# GD32F20x_CL register map
File version: 1.0
CPU: CM3 r2p1, little endian, no MPU, no FPU, 4 interrupt priority bits
Registers are 32-bit, read-write, reset 0x0 unless marked. A register's access mark holds for its fields unless they carry their own. Offsets are from the block's base; [hi:lo] are bit positions; {n}, {i} and the like mark numbered series; 'fields as' and 'values as' point back to an identical list.

## ENET_MSC — Ethernet: MAC statistics counters
Base 0x40028100
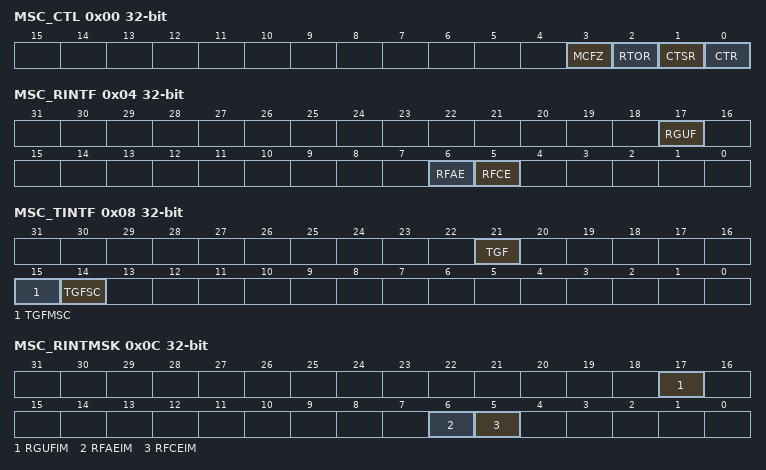
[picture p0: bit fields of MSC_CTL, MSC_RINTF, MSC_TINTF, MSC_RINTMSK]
0x00 MSC_CTL — Ethernet MSC control register (MSC_CTL)
  [3] MCFZ — MSC counter freeze
  [2] RTOR — Reset on read
  [1] CTSR — Counter stop rollover
  [0] CTR — Counter reset
0x04 MSC_RINTF ro — Ethernet MSC receive interrupt flag register (MSC_RINTF)
  [17] RGUF — Received Good Unicast Frames
  [6] RFAE — Received frames alignment error
  [5] RFCE — Received frames CRC error
0x08 MSC_TINTF ro — Ethernet MSC transmit interrupt flag register (MSC_TINTF)
  [21] TGF — Transmitted good frames
  [15] TGFMSC — Transmitted good frames more single collision
  [14] TGFSC — Transmitted good frames single collision
0x0C MSC_RINTMSK — Ethernet MSC receive interrupt mask register (MSC_RINTMSK)
  [17] RGUFIM — Received good unicast frames interrupt mask
  [6] RFAEIM — Received frames alignment error interrupt mask
  [5] RFCEIM — Received frame CRC error interrupt mask
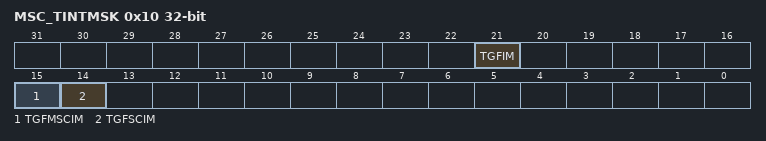
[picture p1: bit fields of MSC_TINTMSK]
0x10 MSC_TINTMSK — Ethernet MSC transmit interrupt mask register (MSC_TINTMSK)
  [21] TGFIM — Transmitted good frames interrupt mask
  [15] TGFMSCIM — Transmitted good frames more single interrupt collision mask
  [14] TGFSCIM — Transmitted good frames single collision interrupt mask
0x4C MSC_SCCNT ro — Ethernet MSC transmitted good frames after a single collision counter
  [31:0] SCC — Transmitted good frames after a single collision counter
0x50 MSC_MSCCNT ro — Ethernet MSC transmitted good frames after more than a single collision
  [31:0] MSCC — Transmitted good frames after more than a single collision counter
0x68 MSC_TGFCNT ro — Ethernet MSC transmitted good frames counter register
  [31:0] TGF — Transmitted good frames counter
0x94 MSC_RFCECNT ro — Ethernet MSC received frames with CRC error counter register
  [31:0] RFCER — Received frames with CRC error counter
0x98 MSC_RFAECNT ro — Ethernet MSC received frames with alignment error counter register
  [31:0] RFAER — Received frames with alignment error counter
0xC4 MSC_RGUFCNT ro — MSC received good unicast frames counter register
  [31:0] RGUF — Received good unicast frames counter

## ENET_PTP — Ethernet: Precision time protocol
Base 0x40028700
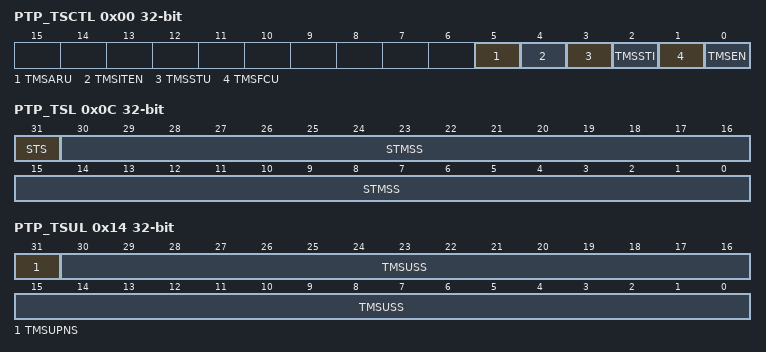
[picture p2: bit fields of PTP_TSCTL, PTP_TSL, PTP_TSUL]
0x00 PTP_TSCTL — Ethernet PTP time stamp control register (PTP_TSCTL)
  [5] TMSARU — Time stamp addend register update
  [4] TMSITEN — Time stamp interrupt trigger enable
  [3] TMSSTU — Time stamp system time update
  [2] TMSSTI — Time stamp system time initialize
  [1] TMSFCU — Time stamp fine or coarse update
  [0] TMSEN — Time stamp enable
0x04 PTP_SSINC — Ethernet PTP subsecond increment register
  [7:0] STMSSI — System time subsecond increment
0x08 PTP_TSH ro — Ethernet PTP time stamp high register
  [31:0] STMS — System time second
0x0C PTP_TSL ro — Ethernet PTP time stamp low register (PTP_TSL)
  [31] STS — System time sign
  [30:0] STMSS — System time subseconds
0x10 PTP_TSUH — Ethernet PTP time stamp high update register
  [31:0] TMSUS — Time stamp update second
0x14 PTP_TSUL — Ethernet PTP time stamp low update register (PTP_TSUL)
  [31] TMSUPNS — Time stamp update positive or negative sign
  [30:0] TMSUSS — Time stamp update subseconds
0x18 PTP_TSADDEND — Ethernet PTP time stamp addend register
  [31:0] TMSA — Time stamp addend
0x1C PTP_ETH — Ethernet PTP expected time high register
  [31:0] ETSH — Expected time stamp high
0x20 PTP_ETL — Ethernet PTP expected time low register
  [31:0] ETSL — Expected time stamp low

## EXMC — External memory controller
Base 0xA0000000
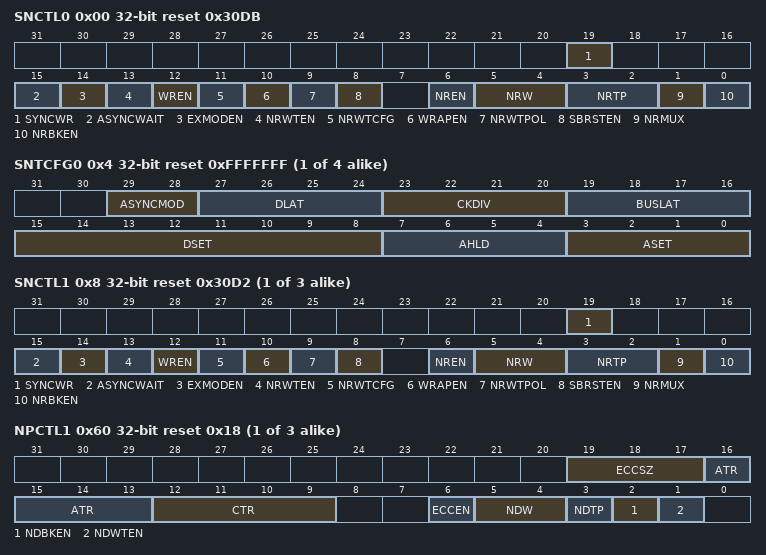
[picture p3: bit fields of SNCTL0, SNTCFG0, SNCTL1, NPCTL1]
0x00 SNCTL0 reset 0x30DB — SRAM/NOR flash control register 0
  [19] SYNCWR — Synchronous write
  [15] ASYNCWAIT — Asynchronous wait
  [14] EXMODEN — Extended mode enable
  [13] NRWTEN — NWAIT signal enable
  [12] WREN — Write enable
  [11] NRWTCFG — NWAIT signal configuration, only work in synchronous mode
  [10] WRAPEN — Wrapped burst mode enable
  [9] NRWTPOL — NWAIT signal polarity
  [8] SBRSTEN — Synchronous burst enable
  [6] NREN — NOR Flash access enable
  [5:4] NRW — NOR bank memory data bus width
  [3:2] NRTP — NOR bank memory type
  [1] NRMUX — NOR bank memory address/data multiplexing
  [0] NRBKEN — NOR bank enable
{0x4+8i} SNTCFG{i} reset 0xFFFFFFF (i=0..3) — SRAM/NOR flash timing configuration register {i}
  [29:28] ASYNCMOD — Asynchronous access mode
  [27:24] DLAT — Data latency for NOR Flash
  [23:20] CKDIV — Synchronous clock divide ratio
  [19:16] BUSLAT — Bus latency
  [15:8] DSET — Data setup time
  [7:4] AHLD — Address hold time
  [3:0] ASET — Address setup time
{0x0+8i} SNCTL{i} reset 0x30D2 (i=1..3) — SRAM/NOR flash control register {i}
  fields as SNCTL0
{0x40+0x20*i} NPCTL{i} reset 0x18 (i=1..3) — NAND flash/PC card control register {i}
  [19:17] ECCSZ — ECC size
  [16:13] ATR — ALE to RE delay
  [12:9] CTR — CLE to RE delay
  [6] ECCEN — ECC enable
  [5:4] NDW — NAND bank memory data bus width
  [3] NDTP — NAND bank memory type
  [2] NDBKEN — NAND bank enable
  [1] NDWTEN — Wait feature enable
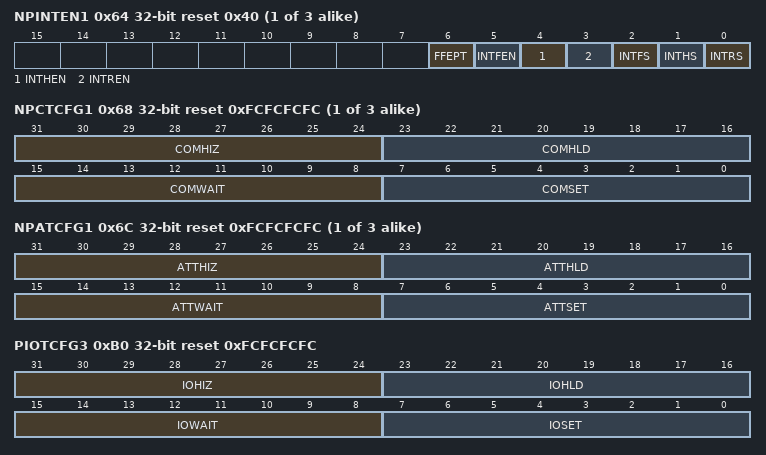
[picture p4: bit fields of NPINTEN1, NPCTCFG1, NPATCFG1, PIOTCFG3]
{0x44+0x20*i} NPINTEN{i} access per field reset 0x40 (i=1..3) — NAND flash/PC card interrupt enable register {i}
  [6] FFEPT ro — FIFO empty flag
  [5] INTFEN rw — Interrupt falling edge detection enable
  [4] INTHEN rw — Interrupt high-level detection enable
  [3] INTREN rw — Interrupt rising edge detection enable bit
  [2] INTFS rw — Interrupt falling edge status
  [1] INTHS rw — Interrupt high-level status
  [0] INTRS rw — Interrupt rising edge status
{0x48+0x20*i} NPCTCFG{i} reset 0xFCFCFCFC (i=1..3) — NAND flash/PC card common space timing configuration register {i}
  [31:24] COMHIZ — Common memory data bus HiZ time
  [23:16] COMHLD — Common memory hold time
  [15:8] COMWAIT — Common memory wait time
  [7:0] COMSET — Common memory setup time
{0x4C+0x20*i} NPATCFG{i} reset 0xFCFCFCFC (i=1..3) — NAND flash/PC card attribute space timing configuration register {i}
  [31:24] ATTHIZ — Attribute memory data bus HiZ time
  [23:16] ATTHLD — Attribute memory hold time
  [15:8] ATTWAIT — Attribute memory wait time
  [7:0] ATTSET — Attribute memory setup time
0x74 NECC1 ro — NAND flash ECC register 1
  [31:0] ECC — ECC result
0x94 NECC2 ro — NAND flash ECC register 2
  [31:0] ECC — ECC result
0xB0 PIOTCFG3 reset 0xFCFCFCFC — PC card I/O space timing configuration register
  [31:24] IOHIZ — IO space data bus HiZ time
  [23:16] IOHLD — IO space hold time
  [15:8] IOWAIT — IO space wait time
  [7:0] IOSET — IO space setup time
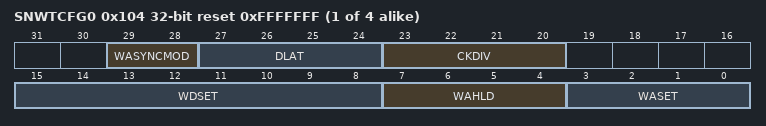
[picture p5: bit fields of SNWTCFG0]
{0x104+8i} SNWTCFG{i} reset 0xFFFFFFF (i=0..3) — SRAM/NOR flash write timing configuration register {i}
  [29:28] WASYNCMOD — Asynchronous access mode
  [27:24] DLAT — Data latency for NOR Flash
  [23:20] CKDIV — Synchronous clock divide ratio
  [15:8] WDSET — Data setup time
  [7:4] WAHLD — Address hold time
  [3:0] WASET — Address setup time
